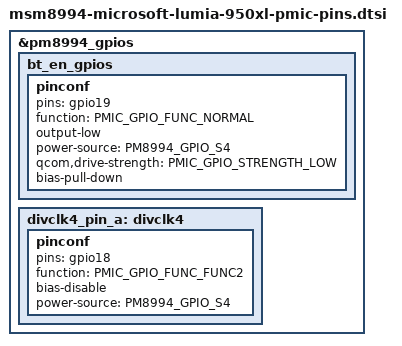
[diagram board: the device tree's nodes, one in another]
// SPDX-License-Identifier: GPL-2.0

#include <dt-bindings/pinctrl/qcom,pmic-gpio.h>
&pm8994_gpios {

    bt_en_gpios: bt_en_gpios {
		pinconf {
			pins = "gpio19";
			function = PMIC_GPIO_FUNC_NORMAL;
			output-low;
			power-source = <PM8994_GPIO_S4>; // 1.8V
			qcom,drive-strength = <PMIC_GPIO_STRENGTH_LOW>;
			bias-pull-down;
		};
	};

    divclk4_pin_a: divclk4 {
		pinconf {
			pins = "gpio18";
			function = PMIC_GPIO_FUNC_FUNC2;

			bias-disable;
			power-source = <PM8994_GPIO_S4>;
		};
	};

};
